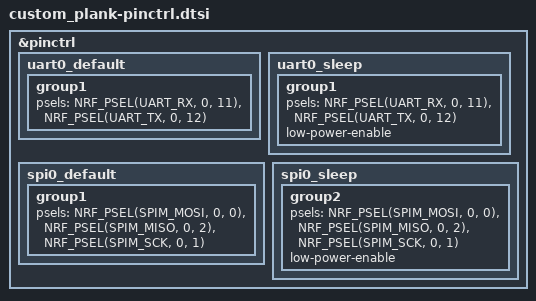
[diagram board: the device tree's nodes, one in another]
&pinctrl {
    uart0_default: uart0_default {
        group1 {
            psels = <NRF_PSEL(UART_RX, 0, 11)>,
                    <NRF_PSEL(UART_TX, 0, 12)>;
        };
    };

    uart0_sleep: uart0_sleep {
        group1 {
            psels = <NRF_PSEL(UART_RX, 0, 11)>,
                    <NRF_PSEL(UART_TX, 0, 12)>;
            low-power-enable;
        };
    };

    spi0_default: spi0_default {
        group1 {
            psels = <NRF_PSEL(SPIM_MOSI, 0, 0)>,
                    <NRF_PSEL(SPIM_MISO, 0, 2)>,
                    <NRF_PSEL(SPIM_SCK, 0, 1)>;
        };
    };

    spi0_sleep: spi0_sleep {
        group2 {
            psels = <NRF_PSEL(SPIM_MOSI, 0, 0)>,
                    <NRF_PSEL(SPIM_MISO, 0, 2)>,
                    <NRF_PSEL(SPIM_SCK, 0, 1)>;
            low-power-enable;
        };
    };
};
